# F28x7x_ecap_regs register map
Vendor: Texas Instruments
Peripheral module from a debugger description file (folder C2000).
Address unit: 16 bits
Registers are 32-bit, read-write, no defined reset value unless marked. A register's access mark holds for its fields unless they carry their own. Offsets are as the file gives them; lines under a group give offsets from that group; [hi:lo] are bit positions; {n}, {i} and the like mark numbered series; 'fields as' and 'values as' point back to an identical list; <NAME> marks a mode.

## ECAP_REGS
0x00 TSCTR — Time-Stamp Counter
  [31:0] TSCTR — Time Stamp Counter
0x02 CTRPHS — Counter Phase Offset Value Register
  [31:0] CTRPHS — Counter phase
0x04 CAP1 — Capture 1 Register
  [31:0] CAP1 — Capture 1
0x06 CAP2 — Capture 2 Register
  [31:0] CAP2 — Capture 2
0x08 CAP3 — Capture 3Register
  [31:0] CAP3 — Capture 3
0x0A CAP4 — Capture 4 Register
  [31:0] CAP4 — Capture 4
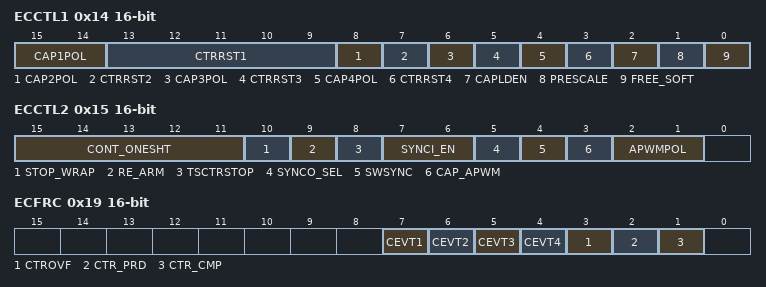
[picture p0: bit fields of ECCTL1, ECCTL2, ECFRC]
0x14 ECCTL1 16-bit — Capture Control Register 1
  [15:14] CAP1POL — Capture Event 1 Polarity select
    0=Capture Event 1 triggered on a rising edge (RE); 1=Capture Event 1 triggered on a falling edge (FE)
  [13:9] CTRRST1 — Counter Reset on Capture Event 1
    0=Do not reset counter on Capture Event 1 (absolute time stamp); 1=Reset counter after Event 1 time-stamp has been captured (used
  [8] CAP2POL — Capture Event 2 Polarity select
    0=Capture Event 2 triggered on a rising edge (RE); 1=Capture Event 2 triggered on a falling edge (FE)
  [7] CTRRST2 — Counter Reset on Capture Event 2
    0=Do not reset counter on Capture Event 2 (absolute time stamp); 1=Reset counter after Event 2 time-stamp has been captured[[br]](
  [6] CAP3POL — Capture Event 3 Polarity select
    0=Capture Event 3 triggered on a rising edge (RE); 1=Capture Event 3 triggered on a falling edge (FE)
  [5] CTRRST3 — Counter Reset on Capture Event 3
    0=Do not reset counter on Capture Event 3 (absolute time stamp); 1=Reset counter after Event 3 time-stamp has been captured[[br]](
  [4] CAP4POL — Capture Event 4 Polarity select
    0=Capture Event 4 triggered on a rising edge (RE); 1=Capture Event 4 triggered on a falling edge (FE)
  [3] CTRRST4 — Counter Reset on Capture Event 4
    0=Do not reset counter on Capture Event 4 (absolute time stamp op; 1=Reset counter after Capture Event 4 time-stamp has been capture
  [2] CAPLDEN — Enable Loading CAP1-4 regs on a Cap Event
    0=Disable CAP1-4 register loads at capture event time; 1=Enable CAP1-4 register loads at capture event time
  [1] PRESCALE — Event Filter prescale select
  [0] FREE_SOFT — Emulation mode
0x15 ECCTL2 16-bit — Capture Control Register 2
  [15:11] CONT_ONESHT — Continuous or one-shot
    0=Operate in continuous mode; 1=Operate in one-Shot mode
  [10] STOP_WRAP — Stop value for one-shot, Wrap for continuous
  [9] RE_ARM — One-shot re-arm
    0=Has no effect (reading always returns a 0); 1=Arms the one-shot sequence as follows:[[br]]1) Resets the Mod4
  [8] TSCTRSTOP — TSCNT counter stop
    0=TSCTR stopped; 1=TSCTR free-running
  [7:6] SYNCI_EN — Counter sync-in select
    0=Disable sync-in option; 1=Enable counter (TSCTR) to be loaded from CTRPHS register upon e
  [5] SYNCO_SEL — Sync-out mode
  [4] SWSYNC — SW forced counter sync
    0=Writing a zero has no effect. Reading always returns a zero; 1=Writing a one forces a TSCTR shadow load of current ECAP module
  [3] CAP_APWM — CAP/APWM operating mode select
    0=ECAP module operates in capture mode; 1=ECAP module operates in APWM mode
  [2:1] APWMPOL — APWM output polarity select
    0=Output is active high (Compare value defines high time); 1=Output is active low (Compare value defines low time)
0x19 ECFRC 16-bit — Capture Interrupt Force Register
  [7] CEVT1 — Capture Event 1 Interrupt Enable
    0=No effect. Always reads back a 0.; 1=Sets the CEVT1 flag bit
  [6] CEVT2 — Capture Event 2 Interrupt Enable
    0=No effect. Always reads back a 0.; 1=Writing a 1 sets the CEVT2 flag bit
  [5] CEVT3 — Capture Event 3 Interrupt Enable
    0=No effect. Always reads back a 0.; 1=Writing a 1 sets the CEVT3 flag bit
  [4] CEVT4 — Capture Event 4 Interrupt Enable
    0=No effect. Always reads back a 0.; 1=Writing a 1 sets the CEVT4 flag bit
  [3] CTROVF — Counter Overflow Interrupt Enable
    0=No effect. Always reads back a 0.; 1=Writing a 1 to this bit sets the CTROVF flag bit
  [2] CTR_PRD — Period Equal Interrupt Enable
    0=No effect. Always reads back a 0.; 1=Writing a 1 sets the CTR=PRD flag bit
  [1] CTR_CMP — Compare Equal Interrupt Enable
    0=No effect. Always reads back a 0.; 1=Writing a 1 sets the CTR=CMP flag bit
